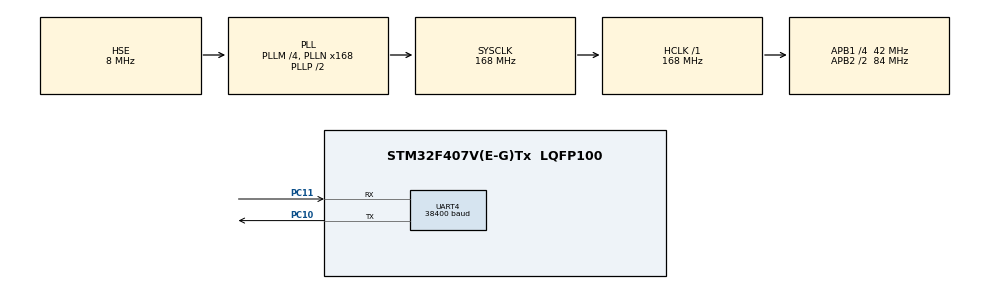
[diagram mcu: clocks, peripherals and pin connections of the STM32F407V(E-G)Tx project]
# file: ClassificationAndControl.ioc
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Mcu.Family=STM32F4
Mcu.Name=STM32F407V(E-G)Tx
Mcu.Package=LQFP100
NVIC.PriorityGroup=NVIC_PRIORITYGROUP_4
PA13.Mode=Serial_Wire
PA13.Signal=SYS_JTMS-SWDIO
PA14.Mode=Serial_Wire
PA14.Signal=SYS_JTCK-SWCLK
PC10.Mode=Asynchronous
PC10.Signal=UART4_TX
PC11.Mode=Asynchronous
PC11.Signal=UART4_RX
PH0-OSC_IN.Mode=HSE-External-Oscillator
PH0-OSC_IN.Signal=RCC_OSC_IN
PH1-OSC_OUT.Mode=HSE-External-Oscillator
PH1-OSC_OUT.Signal=RCC_OSC_OUT
ProjectManager.HeapSize=0x200
ProjectManager.StackSize=0x400
ProjectManager.TargetToolchain=STM32CubeIDE
RCC.48MHZClocksFreq_Value=84000000
RCC.AHBFreq_Value=168000000
RCC.APB1CLKDivider=RCC_HCLK_DIV4
RCC.APB1Freq_Value=42000000
RCC.APB1TimFreq_Value=84000000
RCC.APB2CLKDivider=RCC_HCLK_DIV2
RCC.APB2Freq_Value=84000000
RCC.APB2TimFreq_Value=168000000
RCC.CortexFreq_Value=168000000
RCC.HCLKFreq_Value=168000000
RCC.HSE_VALUE=8000000
RCC.HSI_VALUE=16000000
RCC.LSE_VALUE=32768
RCC.PLLM=4
RCC.PLLN=168
RCC.PLLSourceVirtual=RCC_PLLSOURCE_HSE
RCC.SYSCLKFreq_VALUE=168000000
RCC.SYSCLKSource=RCC_SYSCLKSOURCE_PLLCLK
RCC.VCOOutputFreq_Value=336000000
UART4.BaudRate=38400
UART4.VirtualMode=Asynchronous
board=custom

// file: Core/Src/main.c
/* USER CODE BEGIN Header */
/**
  ******************************************************************************
  * @file           : main.c
  * @brief          : Main program body
  ******************************************************************************
  * @attention
  *
  * <h2><center>&copy; Copyright (c) 2020 STMicroelectronics.
  * All rights reserved.</center></h2>
  *
  * This software component is licensed by ST under BSD 3-Clause license,
  * the "License"; You may not use this file except in compliance with the
  * License. You may obtain a copy of the License at:
  *                        opensource.org/licenses/BSD-3-Clause
  *
  ******************************************************************************
  */
/* USER CODE END Header */

#include "main.h"

/* USER CODE BEGIN Includes */
#include <stdio.h>
#include <string.h>
#include "DCT.h"

/* USER CODE END Includes */

UART_HandleTypeDef huart4;

void SystemClock_Config(void);
static void MX_GPIO_Init(void);
static void MX_UART4_Init(void);

int main(void)
{

  /* MCU Configuration--------------------------------------------------------*/

  /* Reset of all peripherals, Initializes the Flash interface and the Systick. */
  HAL_Init();

  /* Configure the system clock */
  SystemClock_Config();

  /* Initialize all configured peripherals */
  MX_GPIO_Init();
  MX_UART4_Init();

  /* Infinite loop */
  /* USER CODE BEGIN WHILE */
  while (1)
  {
	HAL_UART_Transmit(&huart4, (unsigned char *)"Welcome to Classification and Control!\n", 40, 0xFFFF);
	double* z = dct_test();
	char * str = {0};
	HAL_UART_Transmit(&huart4, (unsigned char*)"Test DCT Coeffs:\n", 18, 0xFFFF);
	char *hello_world = (char*)malloc(2 * sizeof(char));
	sprintf(hello_world, "\n%d, %d, %d, %d, %d, %d, %d, %d, %d, %d, %d, %d, %d, %d, %d, %d, %d, %d, %d, %d, %d, %d, %d, %d, %d, %d, %d, %d, %d, %d, %d, %d\n", (int)(z[0]*100), (int)(z[1]*100), (int)(z[2]*100), (int)(z[3]*100), (int)(z[4]*100), (int)(z[5]*100), (int)(z[6]*100), (int)(z[7]*100), (int)(z[8]*100), (int)(z[9]*100), (int)(z[10]*100), (int)(z[11]*100), (int)(z[12]*100), (int)(z[13]*100), (int)(z[14]*100), (int)(z[15]*100), (int)(z[16]*100), (int)(z[17]*100), (int)(z[18]*100), (int)(z[19]*100), (int)(z[20]*100), (int)(z[21]*100), (int)(z[22]*100), (int)(z[23]*100), (int)(z[24]*100), (int)(z[25]*100), (int)(z[26]*100), (int)(z[27]*100), (int)(z[28]*100), (int)(z[29]*100), (int)(z[30]*100), (int)(z[31]*100));
	HAL_UART_Transmit(&huart4, hello_world, strlen(hello_world), 0xFFFF);
	free(z);
	free(str);
	HAL_Delay(1000);
    /* USER CODE END WHILE */

  }
}

void SystemClock_Config(void)
{
  RCC_OscInitTypeDef RCC_OscInitStruct = {0};
  RCC_ClkInitTypeDef RCC_ClkInitStruct = {0};

  /** Configure the main internal regulator output voltage
  */
  __HAL_RCC_PWR_CLK_ENABLE();
  __HAL_PWR_VOLTAGESCALING_CONFIG(PWR_REGULATOR_VOLTAGE_SCALE1);
  /** Initializes the CPU, AHB and APB busses clocks
  */
  RCC_OscInitStruct.OscillatorType = RCC_OSCILLATORTYPE_HSE;
  RCC_OscInitStruct.HSEState = RCC_HSE_ON;
  RCC_OscInitStruct.PLL.PLLState = RCC_PLL_ON;
  RCC_OscInitStruct.PLL.PLLSource = RCC_PLLSOURCE_HSE;
  RCC_OscInitStruct.PLL.PLLM = 4;
  RCC_OscInitStruct.PLL.PLLN = 168;
  RCC_OscInitStruct.PLL.PLLP = RCC_PLLP_DIV2;
  RCC_OscInitStruct.PLL.PLLQ = 4;
  if (HAL_RCC_OscConfig(&RCC_OscInitStruct) != HAL_OK)
  {
    Error_Handler();
  }
  /** Initializes the CPU, AHB and APB busses clocks
  */
  RCC_ClkInitStruct.ClockType = RCC_CLOCKTYPE_HCLK|RCC_CLOCKTYPE_SYSCLK
                              |RCC_CLOCKTYPE_PCLK1|RCC_CLOCKTYPE_PCLK2;
  RCC_ClkInitStruct.SYSCLKSource = RCC_SYSCLKSOURCE_PLLCLK;
  RCC_ClkInitStruct.AHBCLKDivider = RCC_SYSCLK_DIV1;
  RCC_ClkInitStruct.APB1CLKDivider = RCC_HCLK_DIV4;
  RCC_ClkInitStruct.APB2CLKDivider = RCC_HCLK_DIV2;

  if (HAL_RCC_ClockConfig(&RCC_ClkInitStruct, FLASH_LATENCY_5) != HAL_OK)
  {
    Error_Handler();
  }
}

static void MX_UART4_Init(void)
{

  huart4.Instance = UART4;
  huart4.Init.BaudRate = 38400;
  huart4.Init.WordLength = UART_WORDLENGTH_8B;
  huart4.Init.StopBits = UART_STOPBITS_1;
  huart4.Init.Parity = UART_PARITY_NONE;
  huart4.Init.Mode = UART_MODE_TX_RX;
  huart4.Init.HwFlowCtl = UART_HWCONTROL_NONE;
  huart4.Init.OverSampling = UART_OVERSAMPLING_16;
  if (HAL_UART_Init(&huart4) != HAL_OK)
  {
    Error_Handler();
  }

}

static void MX_GPIO_Init(void)
{

  /* GPIO Ports Clock Enable */
  __HAL_RCC_GPIOH_CLK_ENABLE();
  __HAL_RCC_GPIOA_CLK_ENABLE();
  __HAL_RCC_GPIOC_CLK_ENABLE();

}

void Error_Handler(void)
{
}

/************************ (C) COPYRIGHT STMicroelectronics *****END OF FILE****/
